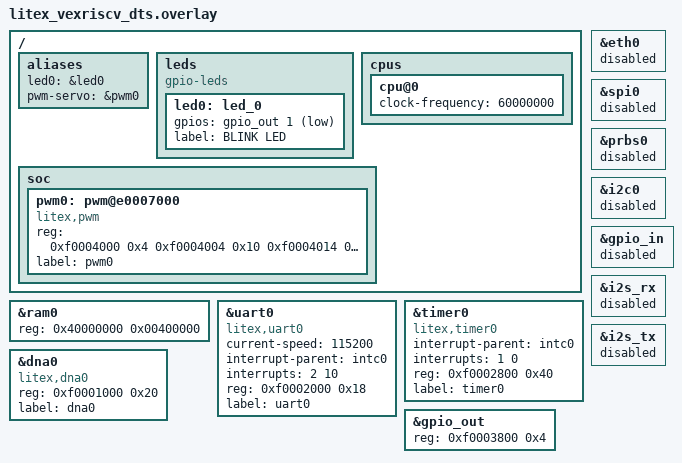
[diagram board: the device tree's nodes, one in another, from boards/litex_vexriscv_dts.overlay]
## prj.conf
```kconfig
CONFIG_STDOUT_CONSOLE=n
CONFIG_ASSERT=n
CONFIG_ASSERT_LEVEL=2
CONFIG_NUM_COOP_PRIORITIES=29
CONFIG_NUM_PREEMPT_PRIORITIES=40
CONFIG_SCHED_SCALABLE=y
CONFIG_MP_NUM_CPUS=1

CONFIG_NETWORKING=n

CONFIG_ETH_LITEETH=n

CONFIG_HWINFO=y

CONFIG_SPI=n

CONFIG_GPIO=y

CONFIG_ENTROPY_LITEX_RNG=n

CONFIG_I2C=n

CONFIG_PWM=y

CONFIG_I2S=n
```

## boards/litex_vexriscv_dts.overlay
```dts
/*
 * Copyright (c) 2018 - 2019 Antmicro <www.antmicro.com>
 *
 * SPDX-License-Identifier: Apache-2.0
 */

/ {
	/* #address-cells = <1>; */
	/* #size-cells = <1>; */
	/* compatible = "litex,vexriscv", "litex-dev"; */
	/* model = "litex,vexriscv"; */


	/* chosen { */
	/* 	zephyr,entropy = &prbs0; */
	/* }; */
  
    aliases {
        led0 = &led0;
    };

	aliases {
		pwm-servo = &pwm0;
	};

	leds {
    compatible = "gpio-leds";
		led0: led_0 {
			gpios = <&gpio_out 1 1>;
			/* gpios = <&gpio_out 0 GPIO_ACTIVE_LOW>; */
			label = "BLINK LED";
		};
	};

	cpus {
		#address-cells = <1>;
		#size-cells = <0>;
		cpu@0 {
			clock-frequency = <60000000>;
			/* compatible = "spinalhdl,vexriscv", "riscv"; */
			/* device_type = "cpu"; */
			/* reg = <0>; */
			/* riscv,isa = "rv32imac"; */
			/* status = "okay"; */
			/* timebase-frequency = <32768>; */
		};
	};
	soc {
		/* #address-cells = <1>; */
		/* #size-cells = <1>; */
		/* compatible = "litex,vexriscv"; */
		/* ranges; */
		/* intc0: interrupt-controller@bc0 { */
		/* 	#interrupt-cells = <2>; */
		/* 	compatible = "vexriscv,intc0"; */
		/* 	interrupt-controller; */
		/* 	reg = <0xbc0 0x4 0xfc0 0x4>; */
		/* 	reg-names = "irq_mask", "irq_pending"; */
		/* 	riscv,max-priority = <7>; */
		/* }; */
		/* uart0: serial@f0002000 { */
		/* 	compatible = "litex,uart0"; */
		/* 	interrupt-parent = <&intc0>; */
		/* 	interrupts = <2 10>; */
		/* 	reg = <0xf0002000 0x18>; */
		/* 	reg-names = "control"; */
		/* 	label = "uart0"; */
		/* 	status = "disabled"; */
		/* }; */
		/* spi0: spi@e0002000 { */
		/* 	compatible = "litex,spi"; */
		/* 	interrupt-parent = <&intc0>; */
		/* 	interrupts = <5 0>; */
		/* 	reg = <0xe0002000 0x34>; */
		/* 	reg-names = "control"; */
		/* 	label = "spi0"; */
		/* 	status = "disabled"; */
		/* 	#address-cells = <1>; */
		/* 	#size-cells = <0>; */
		/* }; */
		/* timer0: timer@e0002800 { */
		/* 	compatible = "litex,timer0"; */
		/* 	interrupt-parent = <&intc0>; */
		/* 	interrupts = <1 0>; */
		/* 	reg = <0xe0002800 0x40>; */
		/* 	reg-names = "control"; */
		/* 	label = "timer0"; */
		/* 	status = "disabled"; */
		/* }; */
		/* eth0: ethernet@e0009800 { */
		/* 	compatible = "litex,eth0"; */
		/* 	interrupt-parent = <&intc0>; */
		/* 	interrupts = <3 0>; */
		/* 	reg = <0xe0009800 0x6b 0xb0000000 0x2000>; */
		/* 	local-mac-address = [10 e2 d5 00 00 02]; */
		/* 	reg-names = "control", "buffers"; */
		/* 	label = "eth0"; */
		/* 	status = "disabled"; */
		/* }; */
		/* dna0: dna@e0003800 { */
		/* 	compatible = "litex,dna0"; */
		/* 	/1* DNA data is 57-bits long, */
		/* 	so it requires 8 bytes. */
		/* 	In LiteX each 32-bit register holds */
		/* 	only a single byte of meaningful data, */
		/* 	hence 8 registers. *1/ */
		/* 	reg = <0xe0003800 0x20>; */
		/* 	reg-names = "mem"; */
		/* 	label = "dna0"; */
		/* 	status = "disabled"; */
		/* }; */
		/* i2c0: i2c@e0005000 { */
		/* 	compatible = "litex,i2c"; */
		/* 	reg = <0xe0005000 0x4 0xe0005004 0x4>; */
		/* 	reg-names = "write", "read"; */
		/* 	label = "i2c0"; */
		/* 	#address-cells = <1>; */
		/* 	#size-cells = <0>; */
		/* 	status = "disabled"; */
		/* }; */
		/* gpio_out: gpio@e0005800 { */
		/* 	compatible = "litex,gpio"; */
		/* 	reg = <0xe0005800 0x4>; */
		/* 	reg-names = "control"; */
		/* 	ngpios = <4>; */
		/* 	label = "gpio_out"; */
		/* 	port-is-output; */
		/* 	status = "disabled"; */
		/* 	gpio-controller; */
		/* 	#gpio-cells = <2>; */
		/* }; */
		/* gpio_in: gpio@e0006000 { */
		/* 	compatible = "litex,gpio"; */
		/* 	reg = <0xe0006000 0x4>; */
		/* 	reg-names = "control"; */
		/* 	ngpios = <4>; */
		/* 	label = "gpio_in"; */
		/* 	status = "disabled"; */
		/* 	gpio-controller; */
		/* 	#gpio-cells = <2>; */
		/* }; */
		/* prbs0: prbs@e0006800 { */
		/* 	compatible = "litex,prbs"; */
		/* 	reg = <0xe0006800 0x4>; */
		/* 	reg-names = "status"; */
		/* 	label = "prbs0"; */
		/* 	status = "disabled"; */
		/* }; */
		pwm0: pwm@e0007000 {
			compatible = "litex,pwm";
			reg = <0xf0004000 0x4 0xf0004004 0x10 0xf0004014 0x10>;
			reg-names = "enable", "width", "period";
			label = "pwm0";
			status = "disabled";
			#pwm-cells = <2>;
		};
		/* i2s_rx: i2s_rx@e000a800 { */
		/* 	compatible = "litex,i2s"; */
		/* 	reg = <0xe000a800 0x20 0xb1000000 0x40000>; */
		/* 	interrupt-parent = <&intc0>; */
		/* 	interrupts = <6 2>; */
		/* 	#address-cells = <1>; */
		/* 	#size-cells = <0>; */
		/* 	reg-names = "control", "fifo"; */
		/* 	fifo_depth = <256>; */
		/* 	label = "i2s_rx"; */
		/* 	status = "disabled"; */
		/* }; */
		/* i2s_tx: i2s_tx@e000b000 { */
		/* 	compatible = "litex,i2s"; */
		/* 	reg = <0xe000b000 0x20 0xb2000000 0x40000>; */
		/* 	interrupt-parent = <&intc0>; */
		/* 	interrupts = <7 2>; */
		/* 	#address-cells = <1>; */
		/* 	#size-cells = <0>; */
		/* 	reg-names = "control", "fifo"; */
		/* 	fifo_depth = <256>; */
		/* 	label = "i2s_tx"; */
		/* 	status = "disabled"; */
		/* }; */
    /* led0: leds@f0003800 { */
    /*   label = "led0"; */
    /*   reg = <0xf0003800 0x4>; */
    /* }; */
	};
};

&ram0 {
  device_type = "memory";
  reg = <0x40000000 0x00400000>;
};

&uart0 {
	status = "okay";
	current-speed = <115200>;
  compatible = "litex,uart0";
  interrupt-parent = <&intc0>;
  interrupts = <2 10>;
  reg = <0xf0002000 0x18>;
  reg-names = "control";
  label = "uart0";
};

&timer0 {
	status = "okay";
  compatible = "litex,timer0";
  interrupt-parent = <&intc0>;
  interrupts = <1 0>;
  reg = <0xf0002800 0x40>;
  reg-names = "control";
  label = "timer0";
};

&eth0 {
	status = "disabled";
};

&dna0 {
	status = "okay";
  compatible = "litex,dna0";
  /* DNA data is 57-bits long,
  so it requires 8 bytes.
  In LiteX each 32-bit register holds
  only a single byte of meaningful data,
  hence 8 registers. */
  /* reg = <0xf0003800 0x20>; */
  reg = <0xf0001000 0x20>;
  reg-names = "mem";
  label = "dna0";
};

&spi0 {
	status = "disabled";
};

&prbs0 {
	status = "disabled";
};

&i2c0 {
	status = "disabled";
	/* label = "I2C_0"; */
};

&pwm0 {
	status = "okay";
	/* clock-prescaler = <3>; */
};

&gpio_out {
	status = "okay";
	reg = <0xf0003800 0x4>;
};

&gpio_in {
	status = "disabled";
};

&i2s_rx {
	status = "disabled";
};

&i2s_tx {
	status = "disabled";
};
```

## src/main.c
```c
#include <zephyr.h>

#if defined(CONFIG_STDOUT_CONSOLE)
#include <stdio.h>
#else
#include <sys/printk.h>
#endif

#include <sys/__assert.h>


#include <device.h>
#include <devicetree.h>
#include <drivers/gpio.h>
#include <drivers/pwm.h>

/* #################### START LED #################### */
#define SLEEP_TIME_MS   250
/* The devicetree node identifier for the "led0" alias. */
#define LED0_NODE DT_ALIAS(led0)

#if DT_NODE_HAS_STATUS(LED0_NODE, okay)
#define LED0	DT_GPIO_LABEL(LED0_NODE, gpios)
#define PIN	DT_GPIO_PIN(LED0_NODE, gpios)
#define FLAGS	DT_GPIO_FLAGS(LED0_NODE, gpios)
#else
/* A build error here means your board isn't set up to blink an LED. */
#error "Unsupported board: led0 devicetree alias is not defined"
#define LED0	""
#define PIN	0
#define FLAGS	0
#endif

/* #################### END LED #################### */

/* #################### START SERVO #################### */
#define PWM_NODE DT_ALIAS(pwm_servo)

#if !DT_NODE_HAS_STATUS(PWM_NODE, okay)
#error "Unsupported board: pwm-servo devicetree alias is not defined or enabled"
#define PWM_LABEL ""
#else
#define PWM_LABEL DT_LABEL(PWM_NODE)
#endif

/*
 * Unlike pulse width, the PWM period is not a critical parameter for
 * motor control. 20 ms is commonly used.
 */
#define PERIOD_USEC	(20U * USEC_PER_MSEC)
#define STEP_USEC	300
#define MIN_PULSE_USEC	500
#define MAX_PULSE_USEC	1300

/* #################### END SERVO #################### */

#define STACK_SIZE (768 + CONFIG_TEST_EXTRA_STACKSIZE)

static K_THREAD_STACK_ARRAY_DEFINE(stacks, 2, STACK_SIZE);
static struct k_thread threads[2];

K_MUTEX_DEFINE( cliblock );	

#include <stdarg.h>

static int32_t get_random_delay(int id, int period_in_ms)
{
	/*
	 * The random delay is unit-less, and is based on the philosopher's ID
	 * and the current uptime to create some pseudo-randomness. It produces
	 * a value between 0 and 31.
	 */
	int32_t delay = (k_uptime_get_32()/100 * (id + 1)) & 0x1f;

	/* add 1 to not generate a delay of 0 */
	int32_t ms = (delay + 1) * period_in_ms;

	return ms;
}

/* #################### START LED #################### */
void blinkLed(void *id, void *unused1, void *unused2)
{
	ARG_UNUSED(unused1);
	ARG_UNUSED(unused2);
	int my_id = POINTER_TO_INT(id);

	const struct device *dev;
	bool led_is_on = true;
	int ret;

	printk("Beginning execution; thread data is %d\n", my_id);
	k_msleep(200);

	dev = device_get_binding(LED0);
	if (dev == NULL) {
		return;
	}

	ret = gpio_pin_configure(dev, PIN, GPIO_OUTPUT_ACTIVE | FLAGS);
	if (ret < 0) {
		return;
	}


	while (1) {
		k_mutex_lock(&cliblock, K_FOREVER);
		/* printk("Thread %d: and now a delay of %d clock ticks\n", my_id, delay); */
		printk("Thread %d \n", my_id);

		gpio_pin_set(dev, PIN, (int)led_is_on);
		led_is_on = !led_is_on;

		k_mutex_unlock(&cliblock);
		k_msleep(SLEEP_TIME_MS);
	}
}
/* #################### END LED #################### */

/* #################### START SERVO #################### */
enum direction {
	DOWN,
	UP,
};

void servo(void *id, void *unused1, void *unused2)
{
	ARG_UNUSED(unused1);
	ARG_UNUSED(unused2);
	int my_id = POINTER_TO_INT(id);

	const struct device *pwm;
	uint32_t pulse_width = MIN_PULSE_USEC;
	enum direction dir = UP;
	int ret;

	printk("Beginning execution; thread data is %d\n", my_id);
	k_msleep(200);

	pwm = device_get_binding(PWM_LABEL);
	if (!pwm) {
		printk("Error: didn't find %s device\n", PWM_LABEL);
		return;
	}

	while (1) {
		k_mutex_lock(&cliblock, K_FOREVER);
		printk("Thread %d \n", my_id);

		ret = pwm_pin_set_usec(pwm, 0, PERIOD_USEC, pulse_width, 0);
		if (ret < 0) {
			printk("Error %d: failed to set pulse width\n", ret);
			return;
		}

		if (dir == DOWN) {
			if (pulse_width <= MIN_PULSE_USEC) {
				dir = UP;
				pulse_width = MIN_PULSE_USEC;
			} else {
				pulse_width -= STEP_USEC;
			}
		} else {
			pulse_width += STEP_USEC;

			if (pulse_width >= MAX_PULSE_USEC) {
				dir = DOWN;
				pulse_width = MAX_PULSE_USEC;
			}
		}
        printk("PWM: %d\n", pulse_width);
		k_mutex_unlock(&cliblock);
		k_sleep(K_SECONDS(1));
	}
}
/* #################### END SERVO #################### */

void philosopher(void *id, void *unused1, void *unused2)
{
	ARG_UNUSED(unused1);
	ARG_UNUSED(unused2);
	
	int my_id = POINTER_TO_INT(id);
	
	printk("Beginning execution; thread data is %d\n", my_id);

	k_msleep(200);

	while (1) {
		int32_t delay;
		
		delay = 200 + get_random_delay(my_id, 25);
		
		k_mutex_lock(&cliblock, K_FOREVER);
		
		printk("Thread %d: and now a delay of %d clock ticks\n", my_id, delay);
		
		k_mutex_unlock(&cliblock);
		
		k_msleep(delay);		
	}
}

static void start_threads(void)
{
	//Crear hilo 0	
	/* k_thread_create(&threads[0], &stacks[0][0], STACK_SIZE, */
	/* 		philosopher, INT_TO_POINTER(0), NULL, NULL, */
	/* 		0, K_USER, K_FOREVER); */
	k_thread_create(&threads[0], &stacks[0][0], STACK_SIZE,
			servo, INT_TO_POINTER(0), NULL, NULL,
			0, K_USER, K_FOREVER);
	
	k_object_access_grant(&cliblock, &threads[0]);
	k_object_access_grant(&cliblock, &threads[1]);
	
	k_thread_start(&threads[0]);
	
	//Crear hilo 1	
	k_thread_create(&threads[1], &stacks[1][0], STACK_SIZE,
		blinkLed, INT_TO_POINTER(1), NULL, NULL,
		0, K_USER, K_FOREVER);	
		
	k_thread_start(&threads[1]);
}

void main(void)
{
	//display_demo_description();
#if CONFIG_TIMESLICING
	k_sched_time_slice_set(5000, 0);
#endif	
	
	k_mutex_init(&cliblock);	//Inicializar Mutex	
	start_threads();

#ifdef CONFIG_COVERAGE
	/* Wait a few seconds before main() exit, giving the sample the
	 * opportunity to dump some output before coverage data gets emitted
	 */
	k_sleep(K_MSEC(5000));
#endif
}
```
